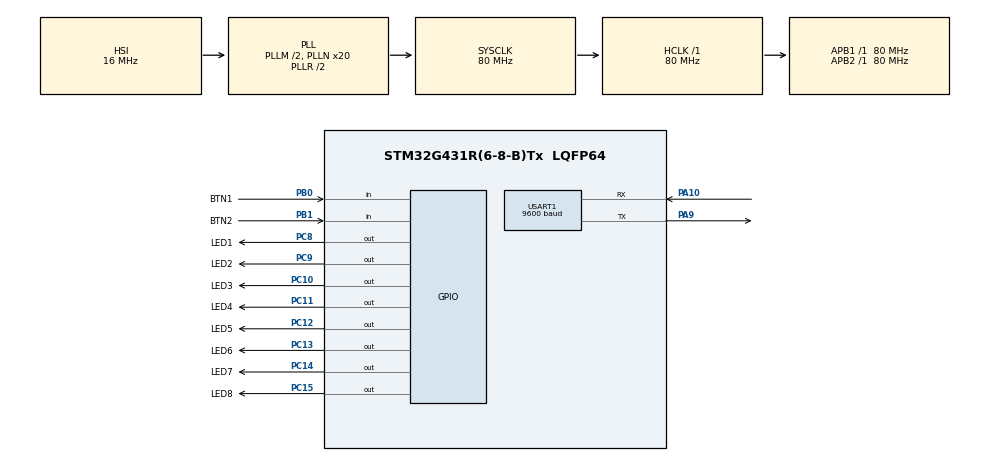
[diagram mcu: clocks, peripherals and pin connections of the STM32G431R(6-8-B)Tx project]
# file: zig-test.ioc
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Mcu.Family=STM32G4
Mcu.Name=STM32G431R(6-8-B)Tx
Mcu.Package=LQFP64
NVIC.PriorityGroup=NVIC_PRIORITYGROUP_4
PA10.GPIO_ModeDefaultPP=GPIO_MODE_AF_PP
PA10.GPIO_PuPd=GPIO_NOPULL
PA10.GPIO_Speed=GPIO_SPEED_FREQ_LOW
PA10.Mode=Asynchronous
PA10.Signal=USART1_RX
PA13.Mode=Serial_Wire
PA13.Signal=SYS_JTMS-SWDIO
PA14.Mode=Serial_Wire
PA14.Signal=SYS_JTCK-SWCLK
PA9.GPIO_ModeDefaultPP=GPIO_MODE_AF_PP
PA9.GPIO_PuPd=GPIO_NOPULL
PA9.GPIO_Speed=GPIO_SPEED_FREQ_LOW
PA9.Mode=Asynchronous
PA9.Signal=USART1_TX
PB0.GPIO_Label=BTN1
PB0.Signal=GPIO_Input
PB1.GPIO_Label=BTN2
PB1.Signal=GPIO_Input
PC10.GPIO_Label=LED3
PC10.GPIO_PuPd=GPIO_PULLUP
PC10.PinState=GPIO_PIN_SET
PC10.Signal=GPIO_Output
PC11.GPIO_Label=LED4
PC11.GPIO_PuPd=GPIO_PULLUP
PC11.PinState=GPIO_PIN_SET
PC11.Signal=GPIO_Output
PC12.GPIO_Label=LED5
PC12.GPIO_PuPd=GPIO_PULLUP
PC12.PinState=GPIO_PIN_SET
PC12.Signal=GPIO_Output
PC13.GPIO_Label=LED6
PC13.GPIO_PuPd=GPIO_PULLUP
PC13.PinState=GPIO_PIN_SET
PC13.Signal=GPIO_Output
PC14-OSC32_IN.GPIO_Label=LED7
PC14-OSC32_IN.GPIO_PuPd=GPIO_PULLUP
PC14-OSC32_IN.PinState=GPIO_PIN_SET
PC14-OSC32_IN.Signal=GPIO_Output
PC15-OSC32_OUT.GPIO_Label=LED8
PC15-OSC32_OUT.GPIO_PuPd=GPIO_PULLUP
PC15-OSC32_OUT.PinState=GPIO_PIN_SET
PC15-OSC32_OUT.Signal=GPIO_Output
PC8.GPIO_Label=LED1
PC8.GPIO_PuPd=GPIO_PULLUP
PC8.PinState=GPIO_PIN_SET
PC8.Signal=GPIO_Output
PC9.GPIO_Label=LED2
PC9.GPIO_PuPd=GPIO_PULLUP
PC9.PinState=GPIO_PIN_SET
PC9.Signal=GPIO_Output
PF0-OSC_IN.Mode=HSE-External-Oscillator
PF0-OSC_IN.Signal=RCC_OSC_IN
PF1-OSC_OUT.Mode=HSE-External-Oscillator
PF1-OSC_OUT.Signal=RCC_OSC_OUT
ProjectManager.HeapSize=0x200
ProjectManager.StackSize=0x400
ProjectManager.TargetToolchain=Makefile
RCC.ADC12Freq_Value=80000000
RCC.AHBFreq_Value=80000000
RCC.APB1Freq_Value=80000000
RCC.APB1TimFreq_Value=80000000
RCC.APB2Freq_Value=80000000
RCC.APB2TimFreq_Value=80000000
RCC.CortexFreq_Value=80000000
RCC.EXTERNAL_CLOCK_VALUE=12288000
RCC.HCLKFreq_Value=80000000
RCC.HSE_VALUE=24000000
RCC.HSI48_VALUE=48000000
RCC.HSI_VALUE=16000000
RCC.LSE_VALUE=32768
RCC.PLLM=RCC_PLLM_DIV2
RCC.PLLN=20
RCC.SYSCLKFreq_VALUE=80000000
RCC.SYSCLKSource=RCC_SYSCLKSOURCE_PLLCLK
RCC.USBFreq_Value=80000000
RCC.VCOOutputFreq_Value=160000000
USART1.BaudRate=9600
USART1.Mode=MODE_TX_RX
USART1.VirtualMode-Asynchronous=VM_ASYNC
VP_SYS_VS_DBSignals.Mode=DisableDeadBatterySignals
board=custom

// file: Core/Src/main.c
/* USER CODE BEGIN Header */
/**
 ******************************************************************************
 * @file           : main.c
 * @brief          : Main program body
 ******************************************************************************
 * @attention
 *
 * Copyright (c) 2026 STMicroelectronics.
 * All rights reserved.
 *
 * This software is licensed under terms that can be found in the LICENSE file
 * in the root directory of this software component.
 * If no LICENSE file comes with this software, it is provided AS-IS.
 *
 ******************************************************************************
 */
/* USER CODE END Header */
#include "main.h"
#include "usart.h"
#include "gpio.h"

/* USER CODE BEGIN PD */
/// NOTE: 这两个是互斥的
/// NOTE: BUILD_BY_EIDE 默认表示用 EIDE 构建，点灯代码在这个文件里
/// NOTE: BUILD_BY_ZIG 表示用 zig 构建，点灯代码在 src/main.zig 里
// #define BUILD_BY_EIDE
#define BUILD_BY_ZIG
/* USER CODE END PD */

void SystemClock_Config(void);

/* USER CODE BEGIN 0 */
#if defined(BUILD_BY_ZIG) && !defined(BUILD_BY_EIDE)
extern void zigMain(void); // 需要 extern 声明以告知编译器确实存在这么个函数
#endif
/* USER CODE END 0 */

int main(void)
{

  /* MCU Configuration--------------------------------------------------------*/

  /* Reset of all peripherals, Initializes the Flash interface and the Systick. */
  HAL_Init();

  /* Configure the system clock */
  SystemClock_Config();

  /* Initialize all configured peripherals */
  MX_GPIO_Init();
  MX_USART1_UART_Init();
  /* USER CODE BEGIN 2 */
#if defined(BUILD_BY_ZIG) && !defined(BUILD_BY_EIDE)
    zigMain(); // 不返回！
#endif
  /* USER CODE END 2 */

  /* Infinite loop */
    while (1)
    {

  }
}

void SystemClock_Config(void)
{
  RCC_OscInitTypeDef RCC_OscInitStruct = {0};
  RCC_ClkInitTypeDef RCC_ClkInitStruct = {0};

  /** Configure the main internal regulator output voltage
  */
  HAL_PWREx_ControlVoltageScaling(PWR_REGULATOR_VOLTAGE_SCALE1);

  /** Initializes the RCC Oscillators according to the specified parameters
  * in the RCC_OscInitTypeDef structure.
  */
  RCC_OscInitStruct.OscillatorType = RCC_OSCILLATORTYPE_HSI;
  RCC_OscInitStruct.HSIState = RCC_HSI_ON;
  RCC_OscInitStruct.HSICalibrationValue = RCC_HSICALIBRATION_DEFAULT;
  RCC_OscInitStruct.PLL.PLLState = RCC_PLL_ON;
  RCC_OscInitStruct.PLL.PLLSource = RCC_PLLSOURCE_HSI;
  RCC_OscInitStruct.PLL.PLLM = RCC_PLLM_DIV2;
  RCC_OscInitStruct.PLL.PLLN = 20;
  RCC_OscInitStruct.PLL.PLLP = RCC_PLLP_DIV2;
  RCC_OscInitStruct.PLL.PLLQ = RCC_PLLQ_DIV2;
  RCC_OscInitStruct.PLL.PLLR = RCC_PLLR_DIV2;
  if (HAL_RCC_OscConfig(&RCC_OscInitStruct) != HAL_OK)
  {
    Error_Handler();
  }

  /** Initializes the CPU, AHB and APB buses clocks
  */
  RCC_ClkInitStruct.ClockType = RCC_CLOCKTYPE_HCLK|RCC_CLOCKTYPE_SYSCLK
                              |RCC_CLOCKTYPE_PCLK1|RCC_CLOCKTYPE_PCLK2;
  RCC_ClkInitStruct.SYSCLKSource = RCC_SYSCLKSOURCE_PLLCLK;
  RCC_ClkInitStruct.AHBCLKDivider = RCC_SYSCLK_DIV1;
  RCC_ClkInitStruct.APB1CLKDivider = RCC_HCLK_DIV1;
  RCC_ClkInitStruct.APB2CLKDivider = RCC_HCLK_DIV1;

  if (HAL_RCC_ClockConfig(&RCC_ClkInitStruct, FLASH_LATENCY_2) != HAL_OK)
  {
    Error_Handler();
  }
}

void Error_Handler(void)
{
    __disable_irq();
    while (1)
    {
    }
}
